# ESP32S31_RADIO register map
Vendor: Espressif; Series: ESP32-S31; File version: 3.52
Registers are 32-bit, read-write, no defined reset value unless marked. A register's access mark holds for its fields unless they carry their own. Offsets are from the block's base; [hi:lo] are bit positions.

## PMU_RADIO — Route-owned PMU words used by the reviewed shared radio clock, RF-power and analog-I2C lifecycles. Unrelated PMU words remain platform-owned.
Base 0x20704000
0x14 HP_ACTIVE_ICG_MODEM reset 0x0 — Active-state modem clock-gating selection.
  [31:30] HP_ACTIVE_DIG_ICG_MODEM_CODE — Two-bit active-state modem clock-gating code; official ESP-HAL publishes code two for the active configuration.
    2=ACTIVE (Active-state modem clock-gating code published by official ESP-HAL.)
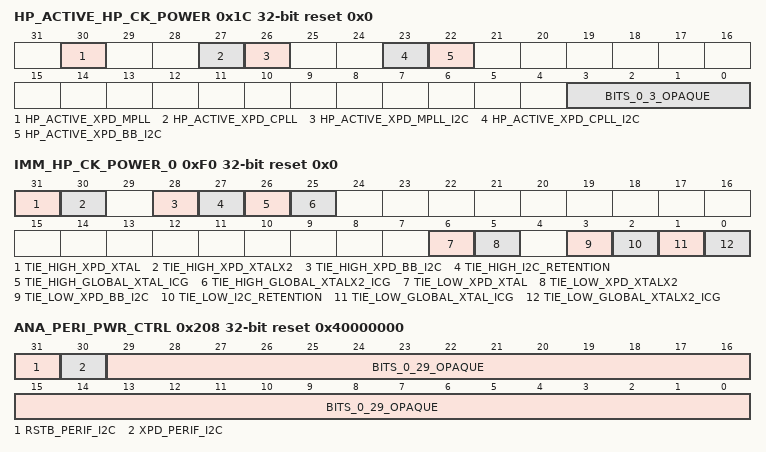
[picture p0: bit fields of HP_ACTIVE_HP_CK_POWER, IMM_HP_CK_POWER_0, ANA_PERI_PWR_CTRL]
0x1C HP_ACTIVE_HP_CK_POWER reset 0x0 — Active-state high-power clock and analog-I2C power control. The public struct calls low4 reserved, but the pinned complete ROM clock leaf explicitly sets them; its direct use overrides that reserved claim on low4 only.
  [30] HP_ACTIVE_XPD_MPLL — Active-state MPLL power. The bootstrap powers it for the PSRAM clock; the radio does not write it.
  [27] HP_ACTIVE_XPD_CPLL — Active-state CPLL power. The bootstrap powers it for the CPU clock; the radio does not write it.
  [26] HP_ACTIVE_XPD_MPLL_I2C — Active-state MPLL analog-I2C power control. The bootstrap powers it before it programs the MPLL that clocks the PSRAM; the radio does not write it.
  [23] HP_ACTIVE_XPD_CPLL_I2C — Active-state CPLL analog-I2C power control. The bootstrap powers it before it programs the CPLL; the radio does not write it.
  [22] HP_ACTIVE_XPD_BB_I2C — Active-state baseband analog-I2C power control.
  [3:0] BITS_0_3_OPAQUE — Opaque: meaning not established. Low-nibble image set by complete rev0 ROM phy_open_fe_bb_clk; individual bit semantics remain unknown.
    on write: 15=ROM_REQUIRED (Complete low-nibble image published by the rev0 ROM front-end/baseband clock leaf.)
0xF0 IMM_HP_CK_POWER_0 reset 0x0 — Immediate high-power clock ties. SOURCE: S31_PMU_HEADERS classes all twelve physical lanes WT; their readback is not established. Writes preserve reserved lanes and clear every sibling trigger from the read image.
  [31] TIE_HIGH_XPD_XTAL — Force the crystal power control high.
  [30] TIE_HIGH_XPD_XTALX2 — Force the doubled-crystal power control high.
  [28] TIE_HIGH_XPD_BB_I2C — Force the baseband analog-I2C power control high.
  [27] TIE_HIGH_I2C_RETENTION
  [26] TIE_HIGH_GLOBAL_XTAL_ICG
  [25] TIE_HIGH_GLOBAL_XTALX2_ICG
  [6] TIE_LOW_XPD_XTAL
  [5] TIE_LOW_XPD_XTALX2
  [3] TIE_LOW_XPD_BB_I2C
  [2] TIE_LOW_I2C_RETENTION
  [1] TIE_LOW_GLOBAL_XTAL_ICG
  [0] TIE_LOW_GLOBAL_XTALX2_ICG
0xF8 IMM_SLEEP_SYSCLK wo reset 0x0 — Immediate sleep/system-clock update commands.
  [28] UPDATE_DIG_ICG_SWITCH — Publish the selected digital clock-gating switch state.
0x104 IMM_MODEM_ICG wo reset 0x0 — Immediate modem clock-gating update command.
  [31] UPDATE_DIG_ICG_MODEM_EN — Publish the selected digital modem clock-gating state.
0x184 RF_PWC reset 0x0 — RF circuit power control.
  [31:16] XPD_RF_CIRCUIT — Sixteen RF circuit power-control bits.
    0=POWERED_OFF (Clear every reviewed RF circuit power-control bit.); 0xFFFF=POWERED_ON (Set every reviewed RF circuit power-control bit.)
0x208 ANA_PERI_PWR_CTRL reset 0x40000000 — Analog peripheral I2C power and active-low reset control.
  [31] RSTB_PERIF_I2C — Analog peripheral I2C active-low reset release.
  [30] XPD_PERIF_I2C — Analog peripheral I2C power control.
  [29:0] BITS_0_29_OPAQUE — Opaque: meaning not established. Observed source use; the individual hardware meaning is unknown.

## HP_SYS_CLKRST_RADIO — Route-owned high-power system clock/reset words shared by the reviewed Wi-Fi, Bluetooth and IEEE 802.15.4 lifecycles. Unrelated HP_SYS_CLKRST words remain platform-owned.
Base 0x20587000
0x40 MODEM_CTRL0 reset 0x1 — Modem control/register-bus clock gate.
  [0] MODEM_CLK_EN — Modem control/register-bus clock enable.
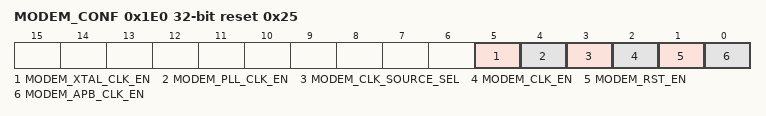
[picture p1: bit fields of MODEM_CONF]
0x1E0 MODEM_CONF reset 0x25 — Modem APB, reset and source-clock configuration.
  [5] MODEM_XTAL_CLK_EN — Modem crystal clock enable.
  [4] MODEM_PLL_CLK_EN — Modem PLL clock enable.
  [3] MODEM_CLK_SOURCE_SEL — Modem source-clock selector.
  [2] MODEM_CLK_EN — Modem source-clock enable.
  [1] MODEM_RST_EN — Modem subsystem reset assertion.
  [0] MODEM_APB_CLK_EN — Modem APB clock enable.
